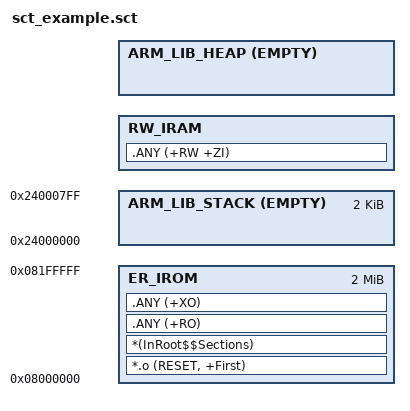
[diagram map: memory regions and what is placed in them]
#! armclang -E --target=arm-arm-none-eabi -mcpu=cortex-m7 -xc
; command above MUST be in first line (no comment above!)

/*
;-------- <<< Use Configuration Wizard in Context Menu >>> -------------------
*/

/*--------------------- Flash Configuration ----------------------------------
; <h> Flash Configuration
;   <o0> Flash Base Address <0x0-0xFFFFFFFF:8>
;   <o1> Flash Size (in Bytes) <0x0-0xFFFFFFFF:8>
; </h>
 *----------------------------------------------------------------------------*/
#define __ROM_BASE      0x08000000
#define __ROM_SIZE      0x00200000

/*--------------------- Embedded RAM Configuration ---------------------------
; <h> RAM Configuration
;   <o0> RAM Base Address    <0x0-0xFFFFFFFF:8>
;   <o1> RAM Size (in Bytes) <0x0-0xFFFFFFFF:8>
; </h>
 *----------------------------------------------------------------------------*/
#define __RAM_BASE      0x24000000
#define __RAM_SIZE      0x00080000

#define __RAM_LIMIT      (__RAM_BASE + __RAM_SIZE)

/*--------------------- Stack / Heap Configuration ---------------------------
; <h> Stack / Heap Configuration
;   <o0> Stack Size (in Bytes) <0x0-0xFFFFFFFF:8>
;   <o1> Heap Size (in Bytes) <0x0-0xFFFFFFFF:8>
; </h>
 *----------------------------------------------------------------------------*/
#define __STACK_SIZE    0x00000800
#define __HEAP_SIZE     0x00000000

/*
;------------- <<< end of configuration section >>> ---------------------------
*/

#if (__HEAP_SIZE == 0x00000000)
#define _HEAP_SIZE_     (__RAM_LIMIT - AlignExpr(ImageLimit(RW_IRAM),8))
#else
#define _HEAP_SIZE_     __HEAP_SIZE
#endif

LR_IROM __ROM_BASE __ROM_SIZE  {    ; load region size_region

    ER_IROM __ROM_BASE __ROM_SIZE  {  ; load address = execution address
        *.o (RESET, +First)
        *(InRoot$$Sections)
        .ANY (+RO)
        .ANY (+XO)
    }

    ARM_LIB_STACK __RAM_BASE ALIGN 8 EMPTY __STACK_SIZE {}

    RW_IRAM +0  {
        .ANY (+RW +ZI)
    }

    ARM_LIB_HEAP +0 ALIGN 8 EMPTY _HEAP_SIZE_ {}

    ScatterAssert(ImageLimit(ARM_LIB_HEAP) <= __RAM_LIMIT)

}

